# CC3200 register map
Vendor: Texas Instruments; Series: SimpleLink; File version: 1.0
CPU: CM4 r0p1, little endian, MPU, no FPU, 3 interrupt priority bits
Registers are 32-bit, read-write, reset 0x0 unless marked. A register's access mark holds for its fields unless they carry their own. Offsets are from the block's base; [hi:lo] are bit positions; {n}, {i} and the like mark numbered series.

## GPRCM
Base 0x4402D000
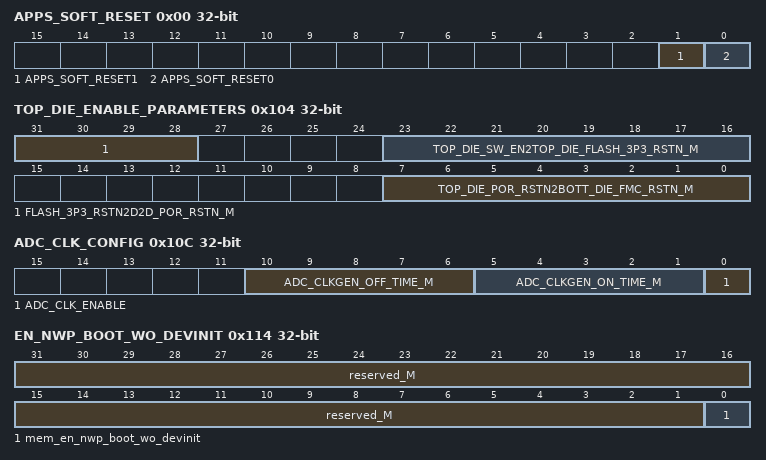
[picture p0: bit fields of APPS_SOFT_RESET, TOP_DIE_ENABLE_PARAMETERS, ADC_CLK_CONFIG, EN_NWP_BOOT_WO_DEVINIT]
0x00 APPS_SOFT_RESET — GPRCM_APPS_SOFT_RESET
  [1] APPS_SOFT_RESET1 — GPRCM_APPS_SOFT_RESET
  [0] APPS_SOFT_RESET0 — GPRCM_APPS_SOFT_RESET
0x04 APPS_LPDS_WAKEUP_CFG — GPRCM_APPS_LPDS_WAKEUP_CFG
  [7:0] APPS_LPDS_WAKEUP_CFG_M
0x08 APPS_LPDS_WAKEUP_SRC — GPRCM_APPS_LPDS_WAKEUP_SRC
  [7:0] APPS_LPDS_WAKEUP_SRC_M
0x0C APPS_RESET_CAUSE — GPRCM_APPS_RESET_CAUSE
  [7:0] APPS_RESET_CAUSE_M
0x10 APPS_LPDS_WAKETIME_OPP_CFG — GPRCM_APPS_LPDS_WAKETIME_OPP_CFG
  [31:0] APPS_LPDS_WAKETIME_OPP_CFG_M
0x18 APPS_SRAM_DSLP_CFG — GPRCM_APPS_SRAM_DSLP_CFG
  [19:0] APPS_SRAM_DSLP_CFG_M
0x1C APPS_SRAM_LPDS_CFG — GPRCM_APPS_SRAM_LPDS_CFG
  [19:0] APPS_SRAM_LPDS_CFG_M
0x20 APPS_LPDS_WAKETIME_WAKE_CFG — GPRCM_APPS_LPDS_WAKETIME_WAKE_CFG
  [31:0] APPS_LPDS_WAKETIME_WAKE_CFG_M
0x100 TOP_DIE_ENABLE — GPRCM_TOP_DIE_ENABLE
  [31:28] PARAMETERS_FLASH_3P3_RSTN2D2D_POR_RSTN_M — GPRCM_TOP_DIE_ENABLE
  [23:16] PARAMETERS_TOP_DIE_SW_EN2TOP_DIE_FLASH_3P3_RSTN_M — GPRCM_TOP_DIE_ENABLE
  [12] FLASH_BUSY — GPRCM_TOP_DIE_ENABLE
  [11:8] TOP_DIE_PWR_PS_M — GPRCM_TOP_DIE_ENABLE
  [1] TOP_DIE_ENABLE_STATUS — GPRCM_TOP_DIE_ENABLE
  [7:0] PARAMETERS_TOP_DIE_POR_RSTN2BOTT_DIE_FMC_RSTN_M — GPRCM_TOP_DIE_ENABLE
  [0] TOP_DIE_ENABLE — GPRCM_TOP_DIE_ENABLE
0x104 TOP_DIE_ENABLE_PARAMETERS — GPRCM_TOP_DIE_ENABLE_PARAMETERS
  [31:28] FLASH_3P3_RSTN2D2D_POR_RSTN_M — GPRCM_TOP_DIE_ENABLE_PARAMETERS
  [23:16] TOP_DIE_SW_EN2TOP_DIE_FLASH_3P3_RSTN_M — GPRCM_TOP_DIE_ENABLE_PARAMETERS
  [7:0] TOP_DIE_POR_RSTN2BOTT_DIE_FMC_RSTN_M — GPRCM_TOP_DIE_ENABLE_PARAMETERS
0x108 MCU_GLOBAL_SOFT_RESET — GPRCM_MCU_GLOBAL_SOFT_RESET
  [0] MCU_GLOBAL_SOFT_RESET
0x10C ADC_CLK_CONFIG — GPRCM_ADC_CLK_CONFIG
  [10:6] ADC_CLKGEN_OFF_TIME_M — GPRCM_ADC_CLK_CONFIG
  [5:1] ADC_CLKGEN_ON_TIME_M — GPRCM_ADC_CLK_CONFIG
  [0] ADC_CLK_ENABLE — GPRCM_ADC_CLK_CONFIG
0x110 APPS_GPIO_WAKE_CONF — GPRCM_APPS_GPIO_WAKE_CONF
  [1:0] APPS_GPIO_WAKE_CONF_M
0x114 EN_NWP_BOOT_WO_DEVINIT — GPRCM_EN_NWP_BOOT_WO_DEVINIT
  [31:1] reserved_M — GPRCM_EN_NWP_BOOT_WO_DEVINIT
  [0] mem_en_nwp_boot_wo_devinit — GPRCM_EN_NWP_BOOT_WO_DEVINIT
0x118 MEM_HCLK_DIV_CFG — GPRCM_MEM_HCLK_DIV_CFG
  [2:0] mem_hclk_div_cfg_M
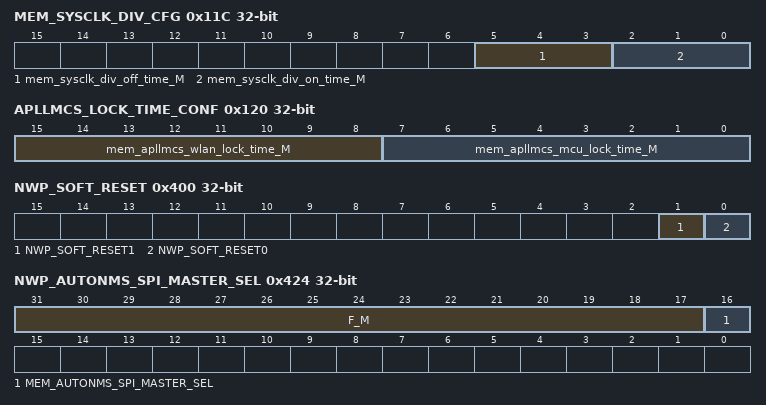
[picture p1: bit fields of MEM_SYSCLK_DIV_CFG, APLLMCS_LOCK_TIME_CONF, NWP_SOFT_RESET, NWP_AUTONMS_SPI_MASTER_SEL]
0x11C MEM_SYSCLK_DIV_CFG — GPRCM_MEM_SYSCLK_DIV_CFG
  [5:3] mem_sysclk_div_off_time_M — GPRCM_MEM_SYSCLK_DIV_CFG
  [2:0] mem_sysclk_div_on_time_M — GPRCM_MEM_SYSCLK_DIV_CFG
0x120 APLLMCS_LOCK_TIME_CONF — GPRCM_APLLMCS_LOCK_TIME_CONF
  [15:8] mem_apllmcs_wlan_lock_time_M — GPRCM_APLLMCS_LOCK_TIME_CONF
  [7:0] mem_apllmcs_mcu_lock_time_M — GPRCM_APLLMCS_LOCK_TIME_CONF
0x400 NWP_SOFT_RESET — GPRCM_NWP_SOFT_RESET
  [1] NWP_SOFT_RESET1 — GPRCM_NWP_SOFT_RESET
  [0] NWP_SOFT_RESET0 — GPRCM_NWP_SOFT_RESET
0x404 NWP_LPDS_WAKEUP_CFG — GPRCM_NWP_LPDS_WAKEUP_CFG
  [7:0] NWP_LPDS_WAKEUP_CFG_M
0x408 NWP_LPDS_WAKEUP_SRC — GPRCM_NWP_LPDS_WAKEUP_SRC
  [7:0] NWP_LPDS_WAKEUP_SRC_M
0x40C NWP_RESET_CAUSE — GPRCM_NWP_RESET_CAUSE
  [7:0] NWP_RESET_CAUSE_M
0x410 NWP_LPDS_WAKETIME_OPP_CFG — GPRCM_NWP_LPDS_WAKETIME_OPP_CFG
  [31:0] NWP_LPDS_WAKETIME_OPP_CFG_M
0x418 NWP_SRAM_DSLP_CFG — GPRCM_NWP_SRAM_DSLP_CFG
  [19:0] NWP_SRAM_DSLP_CFG_M
0x41C NWP_SRAM_LPDS_CFG — GPRCM_NWP_SRAM_LPDS_CFG
  [19:0] NWP_SRAM_LPDS_CFG_M
0x420 NWP_LPDS_WAKETIME_WAKE_CFG — GPRCM_NWP_LPDS_WAKETIME_WAKE_CFG
  [31:0] NWP_LPDS_WAKETIME_WAKE_CFG_M
0x424 NWP_AUTONMS_SPI_MASTER_SEL — GPRCM_NWP_AUTONMS_SPI_MASTER_SEL
  [31:17] F_M — GPRCM_NWP_AUTONMS_SPI_MASTER_SEL
  [16] MEM_AUTONMS_SPI_MASTER_SEL — GPRCM_NWP_AUTONMS_SPI_MASTER_SEL
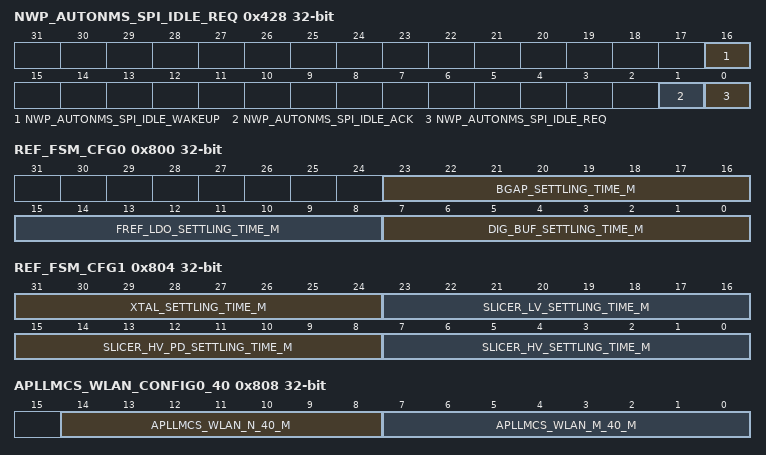
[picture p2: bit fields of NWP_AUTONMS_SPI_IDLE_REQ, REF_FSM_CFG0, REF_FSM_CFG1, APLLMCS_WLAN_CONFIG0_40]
0x428 NWP_AUTONMS_SPI_IDLE_REQ — GPRCM_NWP_AUTONMS_SPI_IDLE_REQ
  [16] NWP_AUTONMS_SPI_IDLE_WAKEUP — GPRCM_NWP_AUTONMS_SPI_IDLE_REQ
  [1] NWP_AUTONMS_SPI_IDLE_ACK — GPRCM_NWP_AUTONMS_SPI_IDLE_REQ
  [0] NWP_AUTONMS_SPI_IDLE_REQ — GPRCM_NWP_AUTONMS_SPI_IDLE_REQ
0x42C WLAN_TO_NWP_WAKE_REQUEST — GPRCM_WLAN_TO_NWP_WAKE_REQUEST
  [0] WLAN_TO_NWP_WAKE_REQUEST
0x430 NWP_TO_WLAN_WAKE_REQUEST — GPRCM_NWP_TO_WLAN_WAKE_REQUEST
  [0] NWP_TO_WLAN_WAKE_REQUEST
0x434 NWP_GPIO_WAKE_CONF — GPRCM_NWP_GPIO_WAKE_CONF
  [1:0] NWP_GPIO_WAKE_CONF_M
0x438 GPRCM_EFUSE_READ_REG12 — GPRCM_GPRCM_EFUSE_READ_REG12
  [15:0] FUSEFARM_ROW_32_MSW_M
0x448 GPRCM_DIEID_READ_REG5 — GPRCM_GPRCM_DIEID_READ_REG5
  [31:0] FUSEFARM_ROW_10_M
0x44C GPRCM_DIEID_READ_REG6 — GPRCM_GPRCM_DIEID_READ_REG6
  [31:0] FUSEFARM_ROW_11_M
0x800 REF_FSM_CFG0 — GPRCM_REF_FSM_CFG0
  [23:16] BGAP_SETTLING_TIME_M — GPRCM_REF_FSM_CFG0
  [15:8] FREF_LDO_SETTLING_TIME_M — GPRCM_REF_FSM_CFG0
  [7:0] DIG_BUF_SETTLING_TIME_M — GPRCM_REF_FSM_CFG0
0x804 REF_FSM_CFG1 — GPRCM_REF_FSM_CFG1
  [31:24] XTAL_SETTLING_TIME_M — GPRCM_REF_FSM_CFG1
  [23:16] SLICER_LV_SETTLING_TIME_M — GPRCM_REF_FSM_CFG1
  [15:8] SLICER_HV_PD_SETTLING_TIME_M — GPRCM_REF_FSM_CFG1
  [7:0] SLICER_HV_SETTLING_TIME_M — GPRCM_REF_FSM_CFG1
0x808 APLLMCS_WLAN_CONFIG0_40 — GPRCM_APLLMCS_WLAN_CONFIG0_40
  [14:8] APLLMCS_WLAN_N_40_M — GPRCM_APLLMCS_WLAN_CONFIG0_40
  [7:0] APLLMCS_WLAN_M_40_M — GPRCM_APLLMCS_WLAN_CONFIG0_40
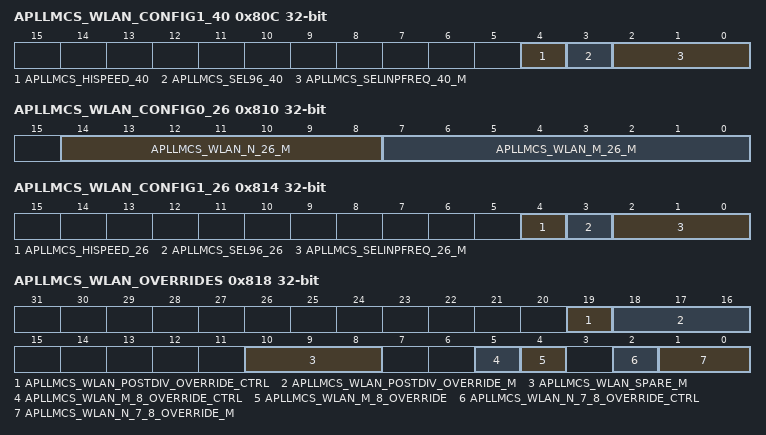
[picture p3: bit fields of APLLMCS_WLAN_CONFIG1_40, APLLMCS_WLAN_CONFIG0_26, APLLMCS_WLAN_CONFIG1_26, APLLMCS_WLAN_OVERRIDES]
0x80C APLLMCS_WLAN_CONFIG1_40 — GPRCM_APLLMCS_WLAN_CONFIG1_40
  [4] APLLMCS_HISPEED_40 — GPRCM_APLLMCS_WLAN_CONFIG1_40
  [3] APLLMCS_SEL96_40 — GPRCM_APLLMCS_WLAN_CONFIG1_40
  [2:0] APLLMCS_SELINPFREQ_40_M — GPRCM_APLLMCS_WLAN_CONFIG1_40
0x810 APLLMCS_WLAN_CONFIG0_26 — GPRCM_APLLMCS_WLAN_CONFIG0_26
  [14:8] APLLMCS_WLAN_N_26_M — GPRCM_APLLMCS_WLAN_CONFIG0_26
  [7:0] APLLMCS_WLAN_M_26_M — GPRCM_APLLMCS_WLAN_CONFIG0_26
0x814 APLLMCS_WLAN_CONFIG1_26 — GPRCM_APLLMCS_WLAN_CONFIG1_26
  [4] APLLMCS_HISPEED_26 — GPRCM_APLLMCS_WLAN_CONFIG1_26
  [3] APLLMCS_SEL96_26 — GPRCM_APLLMCS_WLAN_CONFIG1_26
  [2:0] APLLMCS_SELINPFREQ_26_M — GPRCM_APLLMCS_WLAN_CONFIG1_26
0x818 APLLMCS_WLAN_OVERRIDES — GPRCM_APLLMCS_WLAN_OVERRIDES
  [19] APLLMCS_WLAN_POSTDIV_OVERRIDE_CTRL — GPRCM_APLLMCS_WLAN_OVERRIDES
  [18:16] APLLMCS_WLAN_POSTDIV_OVERRIDE_M — GPRCM_APLLMCS_WLAN_OVERRIDES
  [10:8] APLLMCS_WLAN_SPARE_M — GPRCM_APLLMCS_WLAN_OVERRIDES
  [5] APLLMCS_WLAN_M_8_OVERRIDE_CTRL — GPRCM_APLLMCS_WLAN_OVERRIDES
  [4] APLLMCS_WLAN_M_8_OVERRIDE — GPRCM_APLLMCS_WLAN_OVERRIDES
  [2] APLLMCS_WLAN_N_7_8_OVERRIDE_CTRL — GPRCM_APLLMCS_WLAN_OVERRIDES
  [1:0] APLLMCS_WLAN_N_7_8_OVERRIDE_M — GPRCM_APLLMCS_WLAN_OVERRIDES
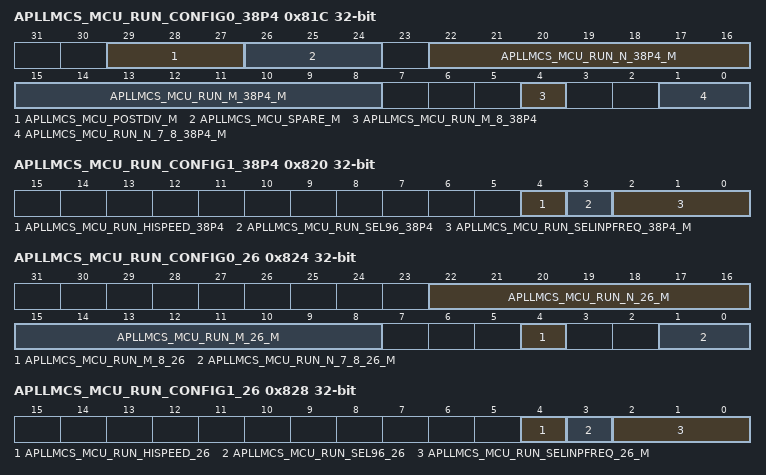
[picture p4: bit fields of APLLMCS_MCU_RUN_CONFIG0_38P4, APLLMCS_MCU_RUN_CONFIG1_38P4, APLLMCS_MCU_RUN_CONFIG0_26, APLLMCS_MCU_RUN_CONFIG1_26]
0x81C APLLMCS_MCU_RUN_CONFIG0_38P4 — GPRCM_APLLMCS_MCU_RUN_CONFIG0_38P4
  [29:27] APLLMCS_MCU_POSTDIV_M — GPRCM_APLLMCS_MCU_RUN_CONFIG0_38P4
  [26:24] APLLMCS_MCU_SPARE_M — GPRCM_APLLMCS_MCU_RUN_CONFIG0_38P4
  [22:16] APLLMCS_MCU_RUN_N_38P4_M — GPRCM_APLLMCS_MCU_RUN_CONFIG0_38P4
  [15:8] APLLMCS_MCU_RUN_M_38P4_M — GPRCM_APLLMCS_MCU_RUN_CONFIG0_38P4
  [4] APLLMCS_MCU_RUN_M_8_38P4 — GPRCM_APLLMCS_MCU_RUN_CONFIG0_38P4
  [1:0] APLLMCS_MCU_RUN_N_7_8_38P4_M — GPRCM_APLLMCS_MCU_RUN_CONFIG0_38P4
0x820 APLLMCS_MCU_RUN_CONFIG1_38P4 — GPRCM_APLLMCS_MCU_RUN_CONFIG1_38P4
  [4] APLLMCS_MCU_RUN_HISPEED_38P4 — GPRCM_APLLMCS_MCU_RUN_CONFIG1_38P4
  [3] APLLMCS_MCU_RUN_SEL96_38P4 — GPRCM_APLLMCS_MCU_RUN_CONFIG1_38P4
  [2:0] APLLMCS_MCU_RUN_SELINPFREQ_38P4_M — GPRCM_APLLMCS_MCU_RUN_CONFIG1_38P4
0x824 APLLMCS_MCU_RUN_CONFIG0_26 — GPRCM_APLLMCS_MCU_RUN_CONFIG0_26
  [22:16] APLLMCS_MCU_RUN_N_26_M — GPRCM_APLLMCS_MCU_RUN_CONFIG0_26
  [15:8] APLLMCS_MCU_RUN_M_26_M — GPRCM_APLLMCS_MCU_RUN_CONFIG0_26
  [4] APLLMCS_MCU_RUN_M_8_26 — GPRCM_APLLMCS_MCU_RUN_CONFIG0_26
  [1:0] APLLMCS_MCU_RUN_N_7_8_26_M — GPRCM_APLLMCS_MCU_RUN_CONFIG0_26
0x828 APLLMCS_MCU_RUN_CONFIG1_26 — GPRCM_APLLMCS_MCU_RUN_CONFIG1_26
  [4] APLLMCS_MCU_RUN_HISPEED_26 — GPRCM_APLLMCS_MCU_RUN_CONFIG1_26
  [3] APLLMCS_MCU_RUN_SEL96_26 — GPRCM_APLLMCS_MCU_RUN_CONFIG1_26
  [2:0] APLLMCS_MCU_RUN_SELINPFREQ_26_M — GPRCM_APLLMCS_MCU_RUN_CONFIG1_26
0x82C SPARE_RW0 — GPRCM_SPARE_RW0
0x830 SPARE_RW1 — GPRCM_SPARE_RW1
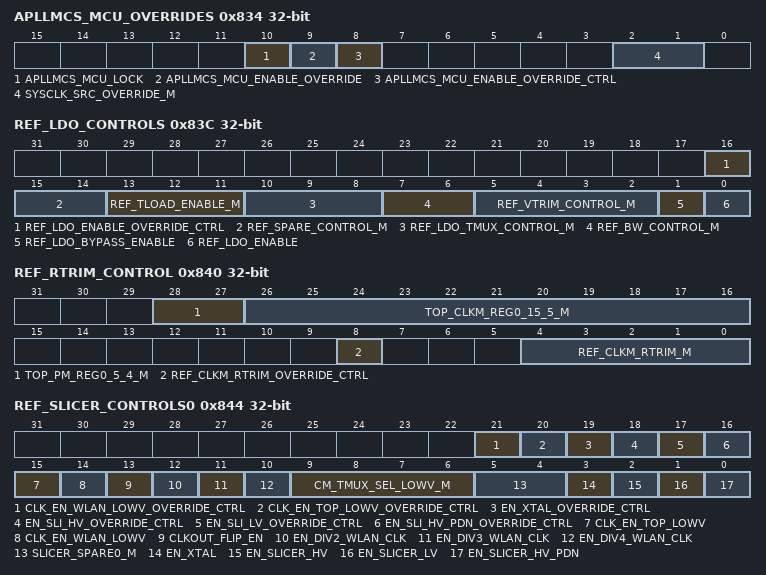
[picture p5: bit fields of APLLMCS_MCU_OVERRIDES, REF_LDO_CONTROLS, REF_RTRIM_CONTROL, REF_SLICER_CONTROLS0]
0x834 APLLMCS_MCU_OVERRIDES — GPRCM_APLLMCS_MCU_OVERRIDES
  [10] APLLMCS_MCU_LOCK — GPRCM_APLLMCS_MCU_OVERRIDES
  [9] APLLMCS_MCU_ENABLE_OVERRIDE — GPRCM_APLLMCS_MCU_OVERRIDES
  [8] APLLMCS_MCU_ENABLE_OVERRIDE_CTRL — GPRCM_APLLMCS_MCU_OVERRIDES
  [2:1] SYSCLK_SRC_OVERRIDE_M — GPRCM_APLLMCS_MCU_OVERRIDES
0x838 SYSCLK_SWITCH_STATUS — GPRCM_SYSCLK_SWITCH_STATUS
  [0] SYSCLK_SWITCH_STATUS
0x83C REF_LDO_CONTROLS — GPRCM_REF_LDO_CONTROLS
  [16] REF_LDO_ENABLE_OVERRIDE_CTRL — GPRCM_REF_LDO_CONTROLS
  [15:14] REF_SPARE_CONTROL_M — GPRCM_REF_LDO_CONTROLS
  [13:11] REF_TLOAD_ENABLE_M — GPRCM_REF_LDO_CONTROLS
  [10:8] REF_LDO_TMUX_CONTROL_M — GPRCM_REF_LDO_CONTROLS
  [7:6] REF_BW_CONTROL_M — GPRCM_REF_LDO_CONTROLS
  [5:2] REF_VTRIM_CONTROL_M — GPRCM_REF_LDO_CONTROLS
  [1] REF_LDO_BYPASS_ENABLE — GPRCM_REF_LDO_CONTROLS
  [0] REF_LDO_ENABLE — GPRCM_REF_LDO_CONTROLS
0x840 REF_RTRIM_CONTROL — GPRCM_REF_RTRIM_CONTROL
  [28:27] TOP_PM_REG0_5_4_M — GPRCM_REF_RTRIM_CONTROL
  [26:16] TOP_CLKM_REG0_15_5_M — GPRCM_REF_RTRIM_CONTROL
  [8] REF_CLKM_RTRIM_OVERRIDE_CTRL — GPRCM_REF_RTRIM_CONTROL
  [4:0] REF_CLKM_RTRIM_M — GPRCM_REF_RTRIM_CONTROL
0x844 REF_SLICER_CONTROLS0 — GPRCM_REF_SLICER_CONTROLS0
  [21] CLK_EN_WLAN_LOWV_OVERRIDE_CTRL — GPRCM_REF_SLICER_CONTROLS0
  [20] CLK_EN_TOP_LOWV_OVERRIDE_CTRL — GPRCM_REF_SLICER_CONTROLS0
  [19] EN_XTAL_OVERRIDE_CTRL — GPRCM_REF_SLICER_CONTROLS0
  [18] EN_SLI_HV_OVERRIDE_CTRL — GPRCM_REF_SLICER_CONTROLS0
  [17] EN_SLI_LV_OVERRIDE_CTRL — GPRCM_REF_SLICER_CONTROLS0
  [16] EN_SLI_HV_PDN_OVERRIDE_CTRL — GPRCM_REF_SLICER_CONTROLS0
  [15] CLK_EN_TOP_LOWV — GPRCM_REF_SLICER_CONTROLS0
  [14] CLK_EN_WLAN_LOWV — GPRCM_REF_SLICER_CONTROLS0
  [13] CLKOUT_FLIP_EN — GPRCM_REF_SLICER_CONTROLS0
  [12] EN_DIV2_WLAN_CLK — GPRCM_REF_SLICER_CONTROLS0
  [11] EN_DIV3_WLAN_CLK — GPRCM_REF_SLICER_CONTROLS0
  [10] EN_DIV4_WLAN_CLK — GPRCM_REF_SLICER_CONTROLS0
  [9:6] CM_TMUX_SEL_LOWV_M — GPRCM_REF_SLICER_CONTROLS0
  [5:4] SLICER_SPARE0_M — GPRCM_REF_SLICER_CONTROLS0
  [3] EN_XTAL — GPRCM_REF_SLICER_CONTROLS0
  [2] EN_SLICER_HV — GPRCM_REF_SLICER_CONTROLS0
  [1] EN_SLICER_LV — GPRCM_REF_SLICER_CONTROLS0
  [0] EN_SLICER_HV_PDN — GPRCM_REF_SLICER_CONTROLS0
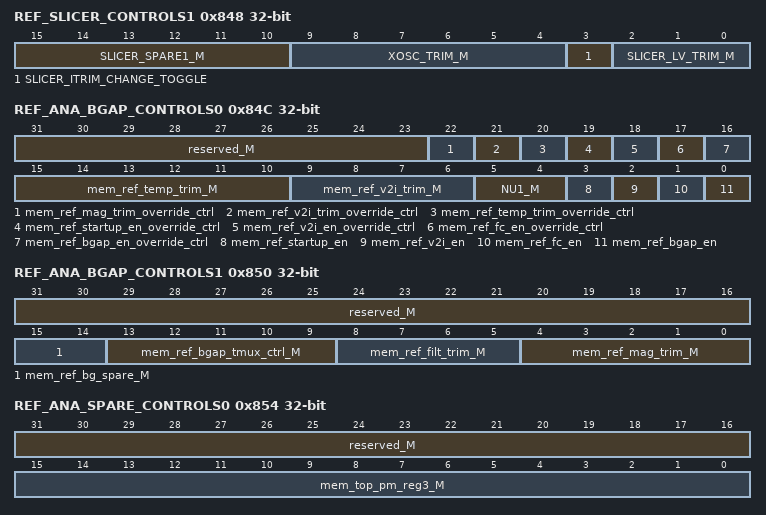
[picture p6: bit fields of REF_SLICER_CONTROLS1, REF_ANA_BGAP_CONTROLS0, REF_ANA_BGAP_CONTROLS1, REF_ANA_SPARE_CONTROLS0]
0x848 REF_SLICER_CONTROLS1 — GPRCM_REF_SLICER_CONTROLS1
  [15:10] SLICER_SPARE1_M — GPRCM_REF_SLICER_CONTROLS1
  [9:4] XOSC_TRIM_M — GPRCM_REF_SLICER_CONTROLS1
  [3] SLICER_ITRIM_CHANGE_TOGGLE — GPRCM_REF_SLICER_CONTROLS1
  [2:0] SLICER_LV_TRIM_M — GPRCM_REF_SLICER_CONTROLS1
0x84C REF_ANA_BGAP_CONTROLS0 — GPRCM_REF_ANA_BGAP_CONTROLS0
  [31:23] reserved_M — GPRCM_REF_ANA_BGAP_CONTROLS0
  [22] mem_ref_mag_trim_override_ctrl — GPRCM_REF_ANA_BGAP_CONTROLS0
  [21] mem_ref_v2i_trim_override_ctrl — GPRCM_REF_ANA_BGAP_CONTROLS0
  [20] mem_ref_temp_trim_override_ctrl — GPRCM_REF_ANA_BGAP_CONTROLS0
  [19] mem_ref_startup_en_override_ctrl — GPRCM_REF_ANA_BGAP_CONTROLS0
  [18] mem_ref_v2i_en_override_ctrl — GPRCM_REF_ANA_BGAP_CONTROLS0
  [17] mem_ref_fc_en_override_ctrl — GPRCM_REF_ANA_BGAP_CONTROLS0
  [16] mem_ref_bgap_en_override_ctrl — GPRCM_REF_ANA_BGAP_CONTROLS0
  [15:10] mem_ref_temp_trim_M — GPRCM_REF_ANA_BGAP_CONTROLS0
  [9:6] mem_ref_v2i_trim_M — GPRCM_REF_ANA_BGAP_CONTROLS0
  [5:4] NU1_M — GPRCM_REF_ANA_BGAP_CONTROLS0
  [3] mem_ref_startup_en — GPRCM_REF_ANA_BGAP_CONTROLS0
  [2] mem_ref_v2i_en — GPRCM_REF_ANA_BGAP_CONTROLS0
  [1] mem_ref_fc_en — GPRCM_REF_ANA_BGAP_CONTROLS0
  [0] mem_ref_bgap_en — GPRCM_REF_ANA_BGAP_CONTROLS0
0x850 REF_ANA_BGAP_CONTROLS1 — GPRCM_REF_ANA_BGAP_CONTROLS1
  [31:16] reserved_M — GPRCM_REF_ANA_BGAP_CONTROLS1
  [15:14] mem_ref_bg_spare_M — GPRCM_REF_ANA_BGAP_CONTROLS1
  [13:9] mem_ref_bgap_tmux_ctrl_M — GPRCM_REF_ANA_BGAP_CONTROLS1
  [8:5] mem_ref_filt_trim_M — GPRCM_REF_ANA_BGAP_CONTROLS1
  [4:0] mem_ref_mag_trim_M — GPRCM_REF_ANA_BGAP_CONTROLS1
0x854 REF_ANA_SPARE_CONTROLS0 — GPRCM_REF_ANA_SPARE_CONTROLS0
  [31:16] reserved_M — GPRCM_REF_ANA_SPARE_CONTROLS0
  [15:0] mem_top_pm_reg3_M — GPRCM_REF_ANA_SPARE_CONTROLS0
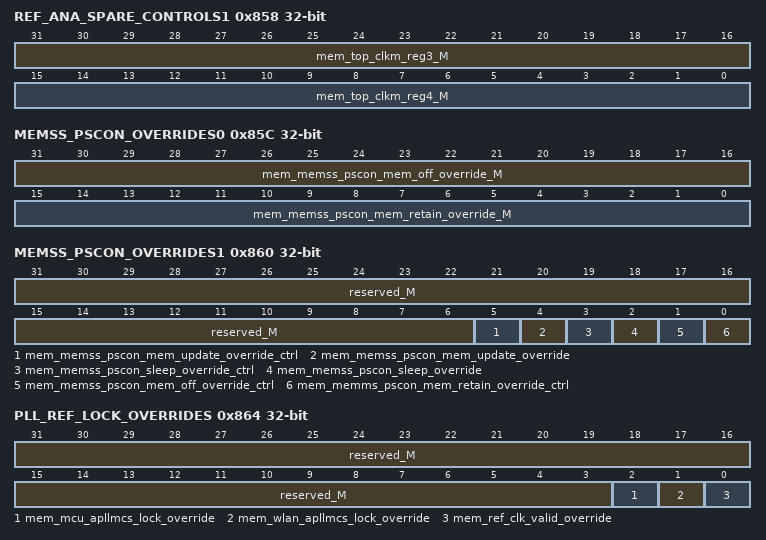
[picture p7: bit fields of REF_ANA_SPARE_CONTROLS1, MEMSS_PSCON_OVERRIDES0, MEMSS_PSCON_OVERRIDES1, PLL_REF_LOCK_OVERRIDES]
0x858 REF_ANA_SPARE_CONTROLS1 — GPRCM_REF_ANA_SPARE_CONTROLS1
  [31:16] mem_top_clkm_reg3_M — GPRCM_REF_ANA_SPARE_CONTROLS1
  [15:0] mem_top_clkm_reg4_M — GPRCM_REF_ANA_SPARE_CONTROLS1
0x85C MEMSS_PSCON_OVERRIDES0 — GPRCM_MEMSS_PSCON_OVERRIDES0
  [31:16] mem_memss_pscon_mem_off_override_M — GPRCM_MEMSS_PSCON_OVERRIDES0
  [15:0] mem_memss_pscon_mem_retain_override_M — GPRCM_MEMSS_PSCON_OVERRIDES0
0x860 MEMSS_PSCON_OVERRIDES1 — GPRCM_MEMSS_PSCON_OVERRIDES1
  [31:6] reserved_M — GPRCM_MEMSS_PSCON_OVERRIDES1
  [5] mem_memss_pscon_mem_update_override_ctrl — GPRCM_MEMSS_PSCON_OVERRIDES1
  [4] mem_memss_pscon_mem_update_override — GPRCM_MEMSS_PSCON_OVERRIDES1
  [3] mem_memss_pscon_sleep_override_ctrl — GPRCM_MEMSS_PSCON_OVERRIDES1
  [2] mem_memss_pscon_sleep_override — GPRCM_MEMSS_PSCON_OVERRIDES1
  [1] mem_memss_pscon_mem_off_override_ctrl — GPRCM_MEMSS_PSCON_OVERRIDES1
  [0] mem_memms_pscon_mem_retain_override_ctrl — GPRCM_MEMSS_PSCON_OVERRIDES1
0x864 PLL_REF_LOCK_OVERRIDES — GPRCM_PLL_REF_LOCK_OVERRIDES
  [31:3] reserved_M — GPRCM_PLL_REF_LOCK_OVERRIDES
  [2] mem_mcu_apllmcs_lock_override — GPRCM_PLL_REF_LOCK_OVERRIDES
  [1] mem_wlan_apllmcs_lock_override — GPRCM_PLL_REF_LOCK_OVERRIDES
  [0] mem_ref_clk_valid_override — GPRCM_PLL_REF_LOCK_OVERRIDES
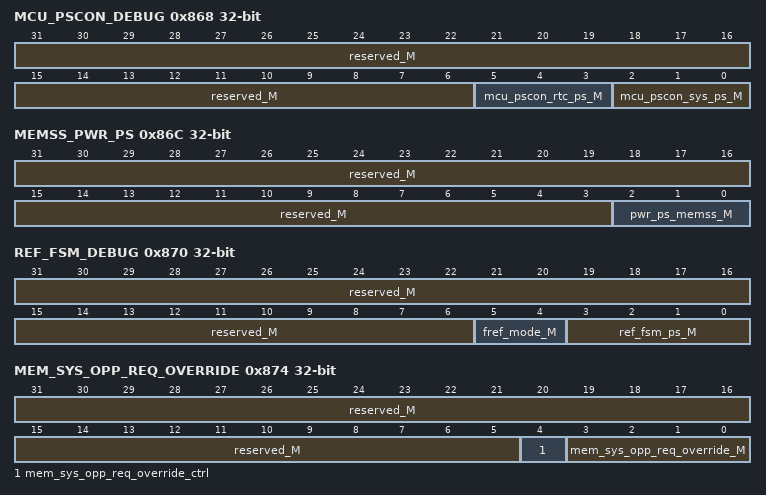
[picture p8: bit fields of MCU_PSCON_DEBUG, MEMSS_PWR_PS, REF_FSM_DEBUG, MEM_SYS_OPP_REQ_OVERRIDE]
0x868 MCU_PSCON_DEBUG — GPRCM_MCU_PSCON_DEBUG
  [31:6] reserved_M — GPRCM_MCU_PSCON_DEBUG
  [5:3] mcu_pscon_rtc_ps_M — GPRCM_MCU_PSCON_DEBUG
  [2:0] mcu_pscon_sys_ps_M — GPRCM_MCU_PSCON_DEBUG
0x86C MEMSS_PWR_PS — GPRCM_MEMSS_PWR_PS
  [31:3] reserved_M — GPRCM_MEMSS_PWR_PS
  [2:0] pwr_ps_memss_M — GPRCM_MEMSS_PWR_PS
0x870 REF_FSM_DEBUG — GPRCM_REF_FSM_DEBUG
  [31:6] reserved_M — GPRCM_REF_FSM_DEBUG
  [5:4] fref_mode_M — GPRCM_REF_FSM_DEBUG
  [3:0] ref_fsm_ps_M — GPRCM_REF_FSM_DEBUG
0x874 MEM_SYS_OPP_REQ_OVERRIDE — GPRCM_MEM_SYS_OPP_REQ_OVERRIDE
  [31:5] reserved_M — GPRCM_MEM_SYS_OPP_REQ_OVERRIDE
  [4] mem_sys_opp_req_override_ctrl — GPRCM_MEM_SYS_OPP_REQ_OVERRIDE
  [3:0] mem_sys_opp_req_override_M — GPRCM_MEM_SYS_OPP_REQ_OVERRIDE
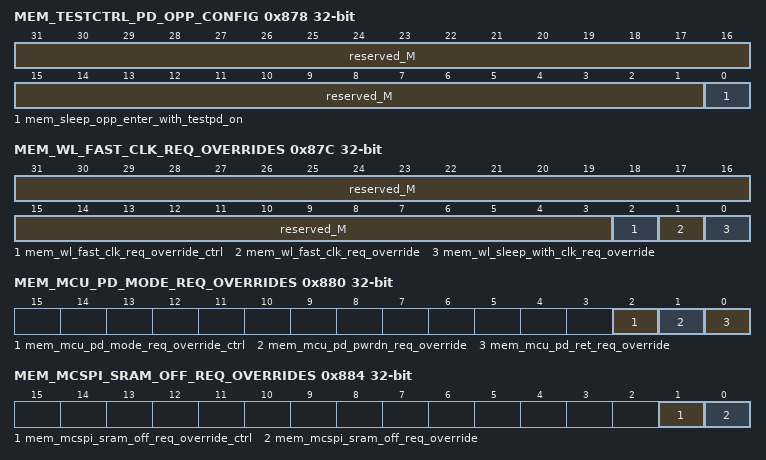
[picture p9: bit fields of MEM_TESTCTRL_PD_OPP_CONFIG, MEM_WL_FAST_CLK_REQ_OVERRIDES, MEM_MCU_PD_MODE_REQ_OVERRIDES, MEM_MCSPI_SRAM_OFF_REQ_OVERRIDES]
0x878 MEM_TESTCTRL_PD_OPP_CONFIG — GPRCM_MEM_TESTCTRL_PD_OPP_CONFIG
  [31:1] reserved_M — GPRCM_MEM_TESTCTRL_PD_OPP_CONFIG
  [0] mem_sleep_opp_enter_with_testpd_on — GPRCM_MEM_TESTCTRL_PD_OPP_CONFIG
0x87C MEM_WL_FAST_CLK_REQ_OVERRIDES — GPRCM_MEM_WL_FAST_CLK_REQ_OVERRIDES
  [31:3] reserved_M — GPRCM_MEM_WL_FAST_CLK_REQ_OVERRIDES
  [2] mem_wl_fast_clk_req_override_ctrl — GPRCM_MEM_WL_FAST_CLK_REQ_OVERRIDES
  [1] mem_wl_fast_clk_req_override — GPRCM_MEM_WL_FAST_CLK_REQ_OVERRIDES
  [0] mem_wl_sleep_with_clk_req_override — GPRCM_MEM_WL_FAST_CLK_REQ_OVERRIDES
0x880 MEM_MCU_PD_MODE_REQ_OVERRIDES — GPRCM_MEM_MCU_PD_MODE_REQ_OVERRIDES
  [2] mem_mcu_pd_mode_req_override_ctrl — GPRCM_MEM_MCU_PD_MODE_REQ_OVERRIDES
  [1] mem_mcu_pd_pwrdn_req_override — GPRCM_MEM_MCU_PD_MODE_REQ_OVERRIDES
  [0] mem_mcu_pd_ret_req_override — GPRCM_MEM_MCU_PD_MODE_REQ_OVERRIDES
0x884 MEM_MCSPI_SRAM_OFF_REQ_OVERRIDES — GPRCM_MEM_MCSPI_SRAM_OFF_REQ_OVERRIDES
  [1] mem_mcspi_sram_off_req_override_ctrl — GPRCM_MEM_MCSPI_SRAM_OFF_REQ_OVERRIDES
  [0] mem_mcspi_sram_off_req_override — GPRCM_MEM_MCSPI_SRAM_OFF_REQ_OVERRIDES
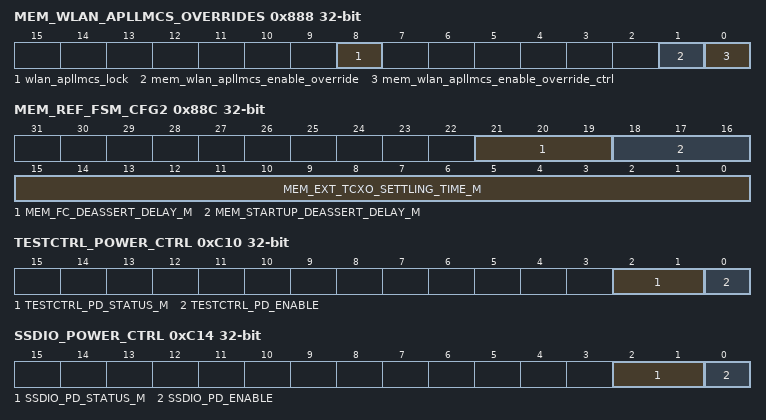
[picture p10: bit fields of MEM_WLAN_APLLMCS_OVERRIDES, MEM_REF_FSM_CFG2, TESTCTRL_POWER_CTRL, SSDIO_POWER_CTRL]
0x888 MEM_WLAN_APLLMCS_OVERRIDES — GPRCM_MEM_WLAN_APLLMCS_OVERRIDES
  [8] wlan_apllmcs_lock — GPRCM_MEM_WLAN_APLLMCS_OVERRIDES
  [1] mem_wlan_apllmcs_enable_override — GPRCM_MEM_WLAN_APLLMCS_OVERRIDES
  [0] mem_wlan_apllmcs_enable_override_ctrl — GPRCM_MEM_WLAN_APLLMCS_OVERRIDES
0x88C MEM_REF_FSM_CFG2 — GPRCM_MEM_REF_FSM_CFG2
  [21:19] MEM_FC_DEASSERT_DELAY_M — GPRCM_MEM_REF_FSM_CFG2
  [18:16] MEM_STARTUP_DEASSERT_DELAY_M — GPRCM_MEM_REF_FSM_CFG2
  [15:0] MEM_EXT_TCXO_SETTLING_TIME_M — GPRCM_MEM_REF_FSM_CFG2
0xC10 TESTCTRL_POWER_CTRL — GPRCM_TESTCTRL_POWER_CTRL
  [2:1] TESTCTRL_PD_STATUS_M — GPRCM_TESTCTRL_POWER_CTRL
  [0] TESTCTRL_PD_ENABLE — GPRCM_TESTCTRL_POWER_CTRL
0xC14 SSDIO_POWER_CTRL — GPRCM_SSDIO_POWER_CTRL
  [2:1] SSDIO_PD_STATUS_M — GPRCM_SSDIO_POWER_CTRL
  [0] SSDIO_PD_ENABLE — GPRCM_SSDIO_POWER_CTRL
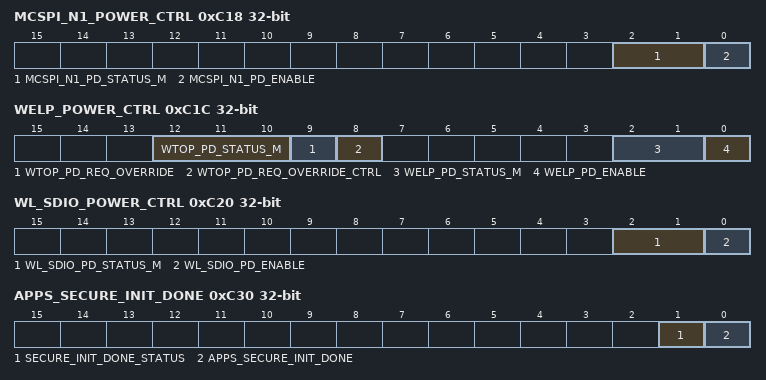
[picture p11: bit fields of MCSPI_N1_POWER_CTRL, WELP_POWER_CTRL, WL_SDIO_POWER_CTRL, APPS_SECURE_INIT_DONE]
0xC18 MCSPI_N1_POWER_CTRL — GPRCM_MCSPI_N1_POWER_CTRL
  [2:1] MCSPI_N1_PD_STATUS_M — GPRCM_MCSPI_N1_POWER_CTRL
  [0] MCSPI_N1_PD_ENABLE — GPRCM_MCSPI_N1_POWER_CTRL
0xC1C WELP_POWER_CTRL — GPRCM_WELP_POWER_CTRL
  [12:10] WTOP_PD_STATUS_M — GPRCM_WELP_POWER_CTRL
  [9] WTOP_PD_REQ_OVERRIDE — GPRCM_WELP_POWER_CTRL
  [8] WTOP_PD_REQ_OVERRIDE_CTRL — GPRCM_WELP_POWER_CTRL
  [2:1] WELP_PD_STATUS_M — GPRCM_WELP_POWER_CTRL
  [0] WELP_PD_ENABLE — GPRCM_WELP_POWER_CTRL
0xC20 WL_SDIO_POWER_CTRL — GPRCM_WL_SDIO_POWER_CTRL
  [2:1] WL_SDIO_PD_STATUS_M — GPRCM_WL_SDIO_POWER_CTRL
  [0] WL_SDIO_PD_ENABLE — GPRCM_WL_SDIO_POWER_CTRL
0xC24 WLAN_SRAM_ACTIVE_PWR_CFG — GPRCM_WLAN_SRAM_ACTIVE_PWR_CFG
  [23:0] WLAN_SRAM_ACTIVE_PWR_CFG_M
0xC28 WLAN_SRAM_SLEEP_PWR_CFG — GPRCM_WLAN_SRAM_SLEEP_PWR_CFG
  [23:0] WLAN_SRAM_SLEEP_PWR_CFG_M
0xC30 APPS_SECURE_INIT_DONE — GPRCM_APPS_SECURE_INIT_DONE
  [1] SECURE_INIT_DONE_STATUS — GPRCM_APPS_SECURE_INIT_DONE
  [0] APPS_SECURE_INIT_DONE — GPRCM_APPS_SECURE_INIT_DONE
0xC34 APPS_DEV_MODE_INIT_DONE — GPRCM_APPS_DEV_MODE_INIT_DONE
  [0] APPS_DEV_MODE_INIT_DONE
0xC38 EN_APPS_REBOOT — GPRCM_EN_APPS_REBOOT
  [0] EN_APPS_REBOOT
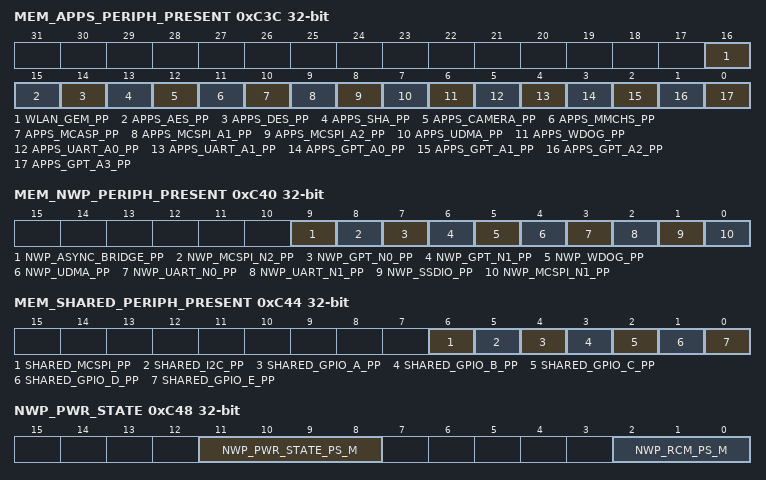
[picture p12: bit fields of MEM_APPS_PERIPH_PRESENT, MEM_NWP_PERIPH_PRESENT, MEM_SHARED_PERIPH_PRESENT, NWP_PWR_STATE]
0xC3C MEM_APPS_PERIPH_PRESENT — GPRCM_MEM_APPS_PERIPH_PRESENT
  [16] WLAN_GEM_PP — GPRCM_MEM_APPS_PERIPH_PRESENT
  [15] APPS_AES_PP — GPRCM_MEM_APPS_PERIPH_PRESENT
  [14] APPS_DES_PP — GPRCM_MEM_APPS_PERIPH_PRESENT
  [13] APPS_SHA_PP — GPRCM_MEM_APPS_PERIPH_PRESENT
  [12] APPS_CAMERA_PP — GPRCM_MEM_APPS_PERIPH_PRESENT
  [11] APPS_MMCHS_PP — GPRCM_MEM_APPS_PERIPH_PRESENT
  [10] APPS_MCASP_PP — GPRCM_MEM_APPS_PERIPH_PRESENT
  [9] APPS_MCSPI_A1_PP — GPRCM_MEM_APPS_PERIPH_PRESENT
  [8] APPS_MCSPI_A2_PP — GPRCM_MEM_APPS_PERIPH_PRESENT
  [7] APPS_UDMA_PP — GPRCM_MEM_APPS_PERIPH_PRESENT
  [6] APPS_WDOG_PP — GPRCM_MEM_APPS_PERIPH_PRESENT
  [5] APPS_UART_A0_PP — GPRCM_MEM_APPS_PERIPH_PRESENT
  [4] APPS_UART_A1_PP — GPRCM_MEM_APPS_PERIPH_PRESENT
  [3-n] APPS_GPT_A{n}_PP (n=0..3) — GPRCM_MEM_APPS_PERIPH_PRESENT
0xC40 MEM_NWP_PERIPH_PRESENT — GPRCM_MEM_NWP_PERIPH_PRESENT
  [9] NWP_ASYNC_BRIDGE_PP — GPRCM_MEM_NWP_PERIPH_PRESENT
  [8] NWP_MCSPI_N2_PP — GPRCM_MEM_NWP_PERIPH_PRESENT
  [7] NWP_GPT_N0_PP — GPRCM_MEM_NWP_PERIPH_PRESENT
  [6] NWP_GPT_N1_PP — GPRCM_MEM_NWP_PERIPH_PRESENT
  [5] NWP_WDOG_PP — GPRCM_MEM_NWP_PERIPH_PRESENT
  [4] NWP_UDMA_PP — GPRCM_MEM_NWP_PERIPH_PRESENT
  [3] NWP_UART_N0_PP — GPRCM_MEM_NWP_PERIPH_PRESENT
  [2] NWP_UART_N1_PP — GPRCM_MEM_NWP_PERIPH_PRESENT
  [1] NWP_SSDIO_PP — GPRCM_MEM_NWP_PERIPH_PRESENT
  [0] NWP_MCSPI_N1_PP — GPRCM_MEM_NWP_PERIPH_PRESENT
0xC44 MEM_SHARED_PERIPH_PRESENT — GPRCM_MEM_SHARED_PERIPH_PRESENT
  [6] SHARED_MCSPI_PP — GPRCM_MEM_SHARED_PERIPH_PRESENT
  [5] SHARED_I2C_PP — GPRCM_MEM_SHARED_PERIPH_PRESENT
  [4] SHARED_GPIO_A_PP — GPRCM_MEM_SHARED_PERIPH_PRESENT
  [3] SHARED_GPIO_B_PP — GPRCM_MEM_SHARED_PERIPH_PRESENT
  [2] SHARED_GPIO_C_PP — GPRCM_MEM_SHARED_PERIPH_PRESENT
  [1] SHARED_GPIO_D_PP — GPRCM_MEM_SHARED_PERIPH_PRESENT
  [0] SHARED_GPIO_E_PP — GPRCM_MEM_SHARED_PERIPH_PRESENT
0xC48 NWP_PWR_STATE — GPRCM_NWP_PWR_STATE
  [11:8] NWP_PWR_STATE_PS_M — GPRCM_NWP_PWR_STATE
  [2:0] NWP_RCM_PS_M — GPRCM_NWP_PWR_STATE
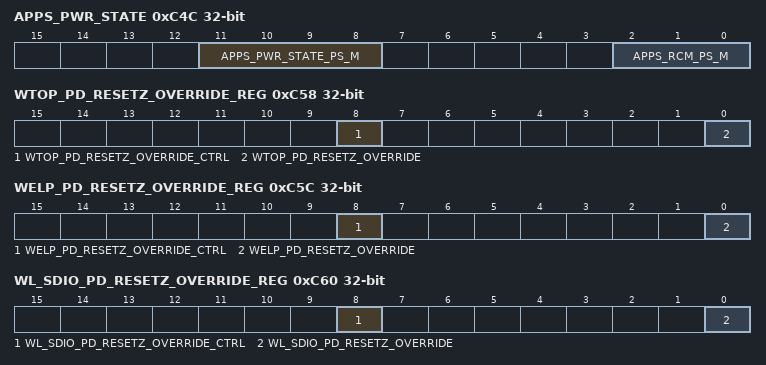
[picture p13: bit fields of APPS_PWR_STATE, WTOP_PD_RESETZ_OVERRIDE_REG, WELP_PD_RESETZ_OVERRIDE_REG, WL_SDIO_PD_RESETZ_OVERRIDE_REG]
0xC4C APPS_PWR_STATE — GPRCM_APPS_PWR_STATE
  [11:8] APPS_PWR_STATE_PS_M — GPRCM_APPS_PWR_STATE
  [2:0] APPS_RCM_PS_M — GPRCM_APPS_PWR_STATE
0xC50 MCU_PWR_STATE — GPRCM_MCU_PWR_STATE
  [4:0] MCU_OPP_PS_M
0xC54 WTOP_PM_PS — GPRCM_WTOP_PM_PS
  [2:0] WTOP_PM_PS_M
0xC58 WTOP_PD_RESETZ_OVERRIDE_REG — GPRCM_WTOP_PD_RESETZ_OVERRIDE_REG
  [8] WTOP_PD_RESETZ_OVERRIDE_CTRL — GPRCM_WTOP_PD_RESETZ_OVERRIDE_REG
  [0] WTOP_PD_RESETZ_OVERRIDE — GPRCM_WTOP_PD_RESETZ_OVERRIDE_REG
0xC5C WELP_PD_RESETZ_OVERRIDE_REG — GPRCM_WELP_PD_RESETZ_OVERRIDE_REG
  [8] WELP_PD_RESETZ_OVERRIDE_CTRL — GPRCM_WELP_PD_RESETZ_OVERRIDE_REG
  [0] WELP_PD_RESETZ_OVERRIDE — GPRCM_WELP_PD_RESETZ_OVERRIDE_REG
0xC60 WL_SDIO_PD_RESETZ_OVERRIDE_REG — GPRCM_WL_SDIO_PD_RESETZ_OVERRIDE_REG
  [8] WL_SDIO_PD_RESETZ_OVERRIDE_CTRL — GPRCM_WL_SDIO_PD_RESETZ_OVERRIDE_REG
  [0] WL_SDIO_PD_RESETZ_OVERRIDE — GPRCM_WL_SDIO_PD_RESETZ_OVERRIDE_REG
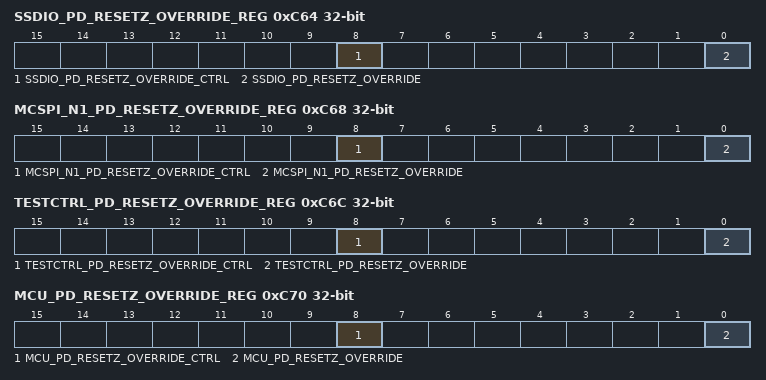
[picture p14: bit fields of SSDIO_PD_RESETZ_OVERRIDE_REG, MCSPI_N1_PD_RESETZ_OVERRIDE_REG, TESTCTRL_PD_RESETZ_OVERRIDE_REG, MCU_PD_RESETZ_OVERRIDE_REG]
0xC64 SSDIO_PD_RESETZ_OVERRIDE_REG — GPRCM_SSDIO_PD_RESETZ_OVERRIDE_REG
  [8] SSDIO_PD_RESETZ_OVERRIDE_CTRL — GPRCM_SSDIO_PD_RESETZ_OVERRIDE_REG
  [0] SSDIO_PD_RESETZ_OVERRIDE — GPRCM_SSDIO_PD_RESETZ_OVERRIDE_REG
0xC68 MCSPI_N1_PD_RESETZ_OVERRIDE_REG — GPRCM_MCSPI_N1_PD_RESETZ_OVERRIDE_REG
  [8] MCSPI_N1_PD_RESETZ_OVERRIDE_CTRL — GPRCM_MCSPI_N1_PD_RESETZ_OVERRIDE_REG
  [0] MCSPI_N1_PD_RESETZ_OVERRIDE — GPRCM_MCSPI_N1_PD_RESETZ_OVERRIDE_REG
0xC6C TESTCTRL_PD_RESETZ_OVERRIDE_REG — GPRCM_TESTCTRL_PD_RESETZ_OVERRIDE_REG
  [8] TESTCTRL_PD_RESETZ_OVERRIDE_CTRL — GPRCM_TESTCTRL_PD_RESETZ_OVERRIDE_REG
  [0] TESTCTRL_PD_RESETZ_OVERRIDE — GPRCM_TESTCTRL_PD_RESETZ_OVERRIDE_REG
0xC70 MCU_PD_RESETZ_OVERRIDE_REG — GPRCM_MCU_PD_RESETZ_OVERRIDE_REG
  [8] MCU_PD_RESETZ_OVERRIDE_CTRL — GPRCM_MCU_PD_RESETZ_OVERRIDE_REG
  [0] MCU_PD_RESETZ_OVERRIDE — GPRCM_MCU_PD_RESETZ_OVERRIDE_REG
0xC78 GPRCM_EFUSE_READ_REG0 — GPRCM_GPRCM_EFUSE_READ_REG0
  [31:0] FUSEFARM_ROW_14_M
0xC7C GPRCM_EFUSE_READ_REG1 — GPRCM_GPRCM_EFUSE_READ_REG1
  [15:0] FUSEFARM_ROW_15_LSW_M — GPRCM_GPRCM_EFUSE_READ_REG1
  [31:0] _FUSEFARM_ROW_23_LSW_ROW_22_MSW_M — GPRCM_GPRCM_EFUSE_READ_REG1
  [31:0] _FUSEFARM_ROW_24_LSW_ROW_23_MSW_M — GPRCM_GPRCM_EFUSE_READ_REG1
  [15:0] _FUSEFARM_ROW_32_MSW_M — GPRCM_GPRCM_EFUSE_READ_REG1
0xC80 GPRCM_EFUSE_READ_REG2 — GPRCM_GPRCM_EFUSE_READ_REG2
  [31:0] FUSEFARM_ROW_16_LSW_ROW_15_MSW_M
0xC84 GPRCM_EFUSE_READ_REG3 — GPRCM_GPRCM_EFUSE_READ_REG3
  [31:0] FUSEFARM_ROW_17_LSW_ROW_16_MSW_M
0xC88 WTOP_MEM_RET_CFG — GPRCM_WTOP_MEM_RET_CFG
  [0] WTOP_MEM_RET_CFG
0xC8C COEX_CLK_SWALLOW_CFG0 — GPRCM_COEX_CLK_SWALLOW_CFG0
  [22:0] Q_FACTOR_M
0xC90 COEX_CLK_SWALLOW_CFG1 — GPRCM_COEX_CLK_SWALLOW_CFG1
  [19:0] P_FACTOR_M
0xC94 COEX_CLK_SWALLOW_CFG2 — GPRCM_COEX_CLK_SWALLOW_CFG2
  [4:3] CONSECUTIVE_SWALLOW_M — GPRCM_COEX_CLK_SWALLOW_CFG2
  [2] PRBS_GAIN — GPRCM_COEX_CLK_SWALLOW_CFG2
  [1] PRBS_ENABLE — GPRCM_COEX_CLK_SWALLOW_CFG2
  [0] SWALLOW_ENABLE — GPRCM_COEX_CLK_SWALLOW_CFG2
0xC98 COEX_CLK_SWALLOW_ENABLE — GPRCM_COEX_CLK_SWALLOW_ENABLE
  [0] COEX_CLK_SWALLOW_ENABLE
0xC9C DCDC_CLK_GEN_CONFIG — GPRCM_DCDC_CLK_GEN_CONFIG
  [0] DCDC_CLK_ENABLE
0xCA0 GPRCM_EFUSE_READ_REG4 — GPRCM_GPRCM_EFUSE_READ_REG4
  [15:0] FUSEFARM_ROW_17_MSW_M
0xCA4 GPRCM_EFUSE_READ_REG5 — GPRCM_GPRCM_EFUSE_READ_REG5
  [31:0] FUSEFARM_ROW_18_M
0xCA8 GPRCM_EFUSE_READ_REG6 — GPRCM_GPRCM_EFUSE_READ_REG6
  [15:0] FUSEFARM_ROW_19_LSW_M
{0xC90+4i} GPRCM_EFUSE_READ_REG{i} (i=7..11) — GPRCM_GPRCM_EFUSE_READ_REG{i}
  [31:0] FUSEFARM_ROW_{i+13}_LSW_ROW_{i+12}_MSW_M
{0xCC0+4i} GPRCM_DIEID_READ_REG{i} (i=0..4) — GPRCM_GPRCM_DIEID_READ_REG{i}
  [31:0] FUSEFARM_{32i+191}_{32i+160}_M
0xCD4 APPS_SS_OVERRIDES — GPRCM_APPS_SS_OVERRIDES
  [31:10] reserved_M — GPRCM_APPS_SS_OVERRIDES
  [9] mem_apps_refclk_gating_override — GPRCM_APPS_SS_OVERRIDES
  [8] mem_apps_refclk_gating_override_ctrl — GPRCM_APPS_SS_OVERRIDES
  [7] mem_apps_pllclk_gating_override — GPRCM_APPS_SS_OVERRIDES
  [6] mem_apps_pllclk_gating_override_ctrl — GPRCM_APPS_SS_OVERRIDES
  [5] mem_apps_por_rstn_override — GPRCM_APPS_SS_OVERRIDES
  [4] mem_apps_sysrstn_override — GPRCM_APPS_SS_OVERRIDES
  [3] mem_apps_sysclk_gating_override — GPRCM_APPS_SS_OVERRIDES
  [2] mem_apps_por_rstn_override_ctrl — GPRCM_APPS_SS_OVERRIDES
  [1] mem_apps_sysrstn_override_ctrl — GPRCM_APPS_SS_OVERRIDES
  [0] mem_apps_sysclk_gating_override_ctrl — GPRCM_APPS_SS_OVERRIDES
0xCD8 NWP_SS_OVERRIDES — GPRCM_NWP_SS_OVERRIDES
  [31:10] reserved_M — GPRCM_NWP_SS_OVERRIDES
  [9] mem_nwp_refclk_gating_override — GPRCM_NWP_SS_OVERRIDES
  [8] mem_nwp_refclk_gating_override_ctrl — GPRCM_NWP_SS_OVERRIDES
  [7] mem_nwp_pllclk_gating_override — GPRCM_NWP_SS_OVERRIDES
  [6] mem_nwp_pllclk_gating_override_ctrl — GPRCM_NWP_SS_OVERRIDES
  [5] mem_nwp_por_rstn_override — GPRCM_NWP_SS_OVERRIDES
  [4] mem_nwp_sysrstn_override — GPRCM_NWP_SS_OVERRIDES
  [3] mem_nwp_sysclk_gating_override — GPRCM_NWP_SS_OVERRIDES
  [2] mem_nwp_por_rstn_override_ctrl — GPRCM_NWP_SS_OVERRIDES
  [1] mem_nwp_sysrstn_override_ctrl — GPRCM_NWP_SS_OVERRIDES
  [0] mem_nwp_sysclk_gating_override_ctrl — GPRCM_NWP_SS_OVERRIDES
0xCDC SHARED_SS_OVERRIDES — GPRCM_SHARED_SS_OVERRIDES
  [31:8] reserved_M — GPRCM_SHARED_SS_OVERRIDES
  [7] mem_shared_pllclk_gating_override_ctrl — GPRCM_SHARED_SS_OVERRIDES
  [6] mem_shared_pllclk_gating_override — GPRCM_SHARED_SS_OVERRIDES
  [5] mem_shared_refclk_gating_override_ctrl — GPRCM_SHARED_SS_OVERRIDES
  [4] mem_shared_refclk_gating_override — GPRCM_SHARED_SS_OVERRIDES
  [3] mem_shared_rstn_override — GPRCM_SHARED_SS_OVERRIDES
  [2] mem_shared_sysclk_gating_override — GPRCM_SHARED_SS_OVERRIDES
  [1] mem_shared_rstn_override_ctrl — GPRCM_SHARED_SS_OVERRIDES
  [0] mem_shared_sysclk_gating_override_ctrl — GPRCM_SHARED_SS_OVERRIDES
0xCE0 IDMEM_CORE_RST_OVERRIDES — GPRCM_IDMEM_CORE_RST_OVERRIDES
  [31:8] reserved_M — GPRCM_IDMEM_CORE_RST_OVERRIDES
  [7] mem_idmem_core_sysrstn_override — GPRCM_IDMEM_CORE_RST_OVERRIDES
  [6] mem_idmem_core_fmc_rstn_override — GPRCM_IDMEM_CORE_RST_OVERRIDES
  [5] SPARE_RW1 — GPRCM_IDMEM_CORE_RST_OVERRIDES
  [4] mem_idmem_core_piosc_gating_override — GPRCM_IDMEM_CORE_RST_OVERRIDES
  [3] mem_idmem_core_sysrstn_override_ctrl — GPRCM_IDMEM_CORE_RST_OVERRIDES
  [2] mem_idmem_core_fmc_rstn_override_ctrl — GPRCM_IDMEM_CORE_RST_OVERRIDES
  [1] SPARE_RW0 — GPRCM_IDMEM_CORE_RST_OVERRIDES
  [0] mem_idmem_core_piosc_gating_override_ctrl — GPRCM_IDMEM_CORE_RST_OVERRIDES
0xCE4 TOP_DIE_FSM_OVERRIDES — GPRCM_TOP_DIE_FSM_OVERRIDES
  [31:12] reserved_M — GPRCM_TOP_DIE_FSM_OVERRIDES
  [11] mem_d2d_pwr_switch_pgoodin_override_ctrl — GPRCM_TOP_DIE_FSM_OVERRIDES
  [10] mem_d2d_pwr_switch_pgoodin_override — GPRCM_TOP_DIE_FSM_OVERRIDES
  [9] mem_d2d_hclk_gating_override — GPRCM_TOP_DIE_FSM_OVERRIDES
  [8] mem_d2d_piosc_gating_override — GPRCM_TOP_DIE_FSM_OVERRIDES
  [7] mem_d2d_rstn_override — GPRCM_TOP_DIE_FSM_OVERRIDES
  [6] mem_d2d_pwr_switch_ponin_override — GPRCM_TOP_DIE_FSM_OVERRIDES
  [5] mem_flash_ready_override — GPRCM_TOP_DIE_FSM_OVERRIDES
  [4] mem_d2d_hclk_gating_override_ctrl — GPRCM_TOP_DIE_FSM_OVERRIDES
  [3] mem_d2d_piosc_gating_override_ctrl — GPRCM_TOP_DIE_FSM_OVERRIDES
  [2] mem_d2d_rstn_override_ctrl — GPRCM_TOP_DIE_FSM_OVERRIDES
  [1] mem_d2d_pwr_switch_ponin_override_ctrl — GPRCM_TOP_DIE_FSM_OVERRIDES
  [0] mem_flash_ready_override_ctrl — GPRCM_TOP_DIE_FSM_OVERRIDES
0xCE8 MCU_PSCON_OVERRIDES — GPRCM_MCU_PSCON_OVERRIDES
  [31:20] reserved_M — GPRCM_MCU_PSCON_OVERRIDES
  [19] mem_mcu_pscon_mem_sleep_override_ctrl — GPRCM_MCU_PSCON_OVERRIDES
  [18] mem_mcu_pscon_mem_update_override_ctrl — GPRCM_MCU_PSCON_OVERRIDES
  [17] mem_mcu_pscon_mem_off_override_ctrl — GPRCM_MCU_PSCON_OVERRIDES
  [16] mem_mcu_pscon_mem_retain_override_ctrl — GPRCM_MCU_PSCON_OVERRIDES
  [15:10] NU1_M — GPRCM_MCU_PSCON_OVERRIDES
  [9] mem_mcu_pscon_sleep_override — GPRCM_MCU_PSCON_OVERRIDES
  [8] mem_mcu_pscon_mem_update_override — GPRCM_MCU_PSCON_OVERRIDES
  [7:4] mem_mcu_pscon_mem_off_override_M — GPRCM_MCU_PSCON_OVERRIDES
  [3:0] mem_mcu_pscon_mem_retain_override_M — GPRCM_MCU_PSCON_OVERRIDES
0xCEC WTOP_PSCON_OVERRIDES — GPRCM_WTOP_PSCON_OVERRIDES
  [31:22] reserved_M — GPRCM_WTOP_PSCON_OVERRIDES
  [21] mem_wtop_pscon_sleep_override_ctrl — GPRCM_WTOP_PSCON_OVERRIDES
  [20] mem_wtop_pscon_mem_update_override_ctrl — GPRCM_WTOP_PSCON_OVERRIDES
  [19] mem_wtop_pscon_mem_off_override_ctrl — GPRCM_WTOP_PSCON_OVERRIDES
  [18] mem_wtop_pscon_mem_retain_override_ctrl — GPRCM_WTOP_PSCON_OVERRIDES
  [17] mem_wtop_pscon_sleep_override — GPRCM_WTOP_PSCON_OVERRIDES
  [16] mem_wtop_pscon_mem_update_override — GPRCM_WTOP_PSCON_OVERRIDES
  [15:8] mem_wtop_pscon_mem_off_override_M — GPRCM_WTOP_PSCON_OVERRIDES
  [7:0] mem_wtop_pscon_mem_retain_override_M — GPRCM_WTOP_PSCON_OVERRIDES
0xCF0 WELP_PSCON_OVERRIDES — GPRCM_WELP_PSCON_OVERRIDES
  [31:2] reserved_M — GPRCM_WELP_PSCON_OVERRIDES
  [1] mem_welp_pscon_sleep_override_ctrl — GPRCM_WELP_PSCON_OVERRIDES
  [0] mem_welp_pscon_sleep_override — GPRCM_WELP_PSCON_OVERRIDES
0xCF4 WL_SDIO_PSCON_OVERRIDES — GPRCM_WL_SDIO_PSCON_OVERRIDES
  [31:2] reserved_M — GPRCM_WL_SDIO_PSCON_OVERRIDES
  [1] mem_wl_sdio_pscon_sleep_override_ctrl — GPRCM_WL_SDIO_PSCON_OVERRIDES
  [0] mem_wl_sdio_pscon_sleep_override — GPRCM_WL_SDIO_PSCON_OVERRIDES
0xCF8 MCSPI_PSCON_OVERRIDES — GPRCM_MCSPI_PSCON_OVERRIDES
  [31:8] reserved_M — GPRCM_MCSPI_PSCON_OVERRIDES
  [7] mem_mcspi_pscon_mem_retain_override_ctrl — GPRCM_MCSPI_PSCON_OVERRIDES
  [6] mem_mcspi_pscon_mem_off_override_ctrl — GPRCM_MCSPI_PSCON_OVERRIDES
  [5] mem_mcspi_pscon_mem_retain_override — GPRCM_MCSPI_PSCON_OVERRIDES
  [4] mem_mcspi_pscon_mem_off_override — GPRCM_MCSPI_PSCON_OVERRIDES
  [3] mem_mcspi_pscon_mem_update_override_ctrl — GPRCM_MCSPI_PSCON_OVERRIDES
  [2] mem_mcspi_pscon_mem_update_override — GPRCM_MCSPI_PSCON_OVERRIDES
  [1] mem_mcspi_pscon_sleep_override_ctrl — GPRCM_MCSPI_PSCON_OVERRIDES
  [0] mem_mcspi_pscon_sleep_override — GPRCM_MCSPI_PSCON_OVERRIDES
0xCFC SSDIO_PSCON_OVERRIDES — GPRCM_SSDIO_PSCON_OVERRIDES
  [31:2] reserved_M — GPRCM_SSDIO_PSCON_OVERRIDES
  [1] mem_ssdio_pscon_sleep_override_ctrl — GPRCM_SSDIO_PSCON_OVERRIDES
  [0] mem_ssdio_pscon_sleep_override — GPRCM_SSDIO_PSCON_OVERRIDES
